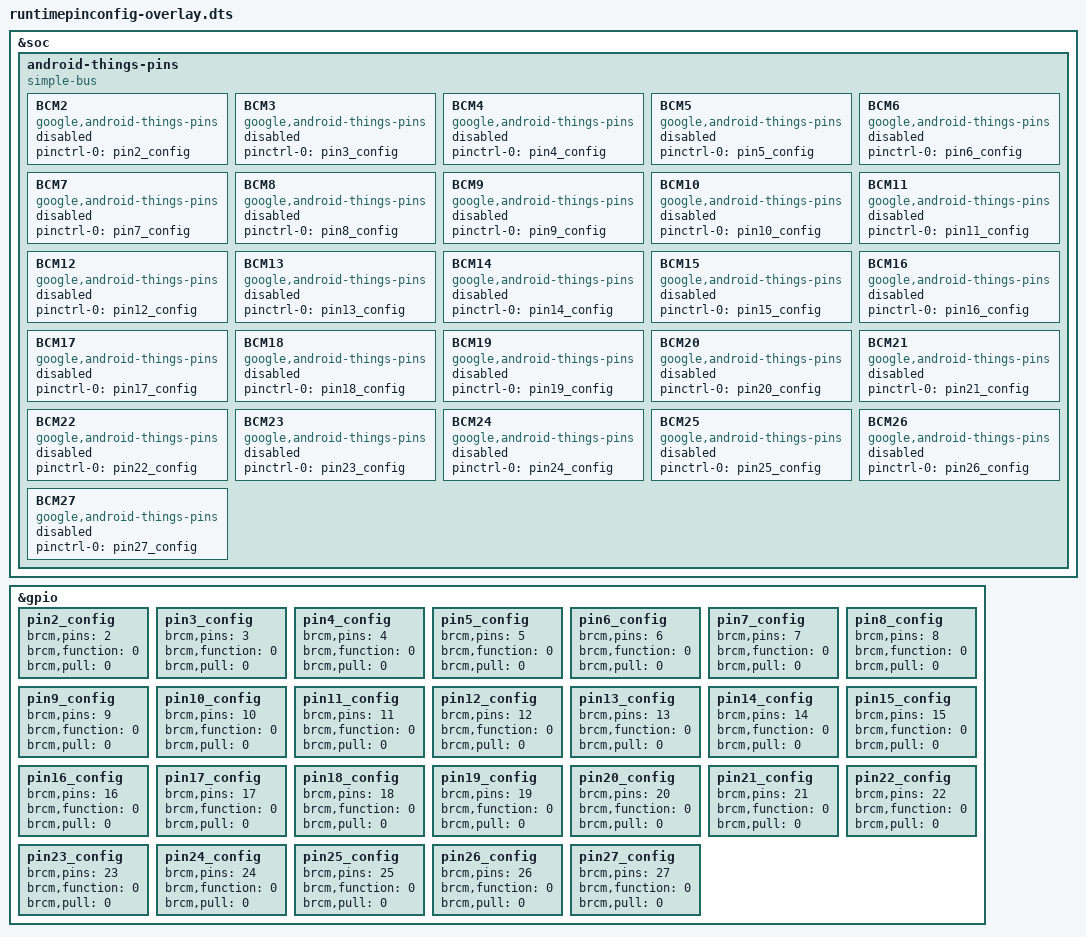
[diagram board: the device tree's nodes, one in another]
/dts-v1/;
/plugin/;

/ {
  fragment@0 {
    target = <&soc>;
    __overlay__ {
      android-things-pins {
        compatible = "simple-bus";

        BCM2 {
          compatible = "google,android-things-pins";
          pinctrl-names = "default";
          pinctrl-0 = <&pin2_config>;
          status = "disabled";
        };

        BCM3 {
          compatible = "google,android-things-pins";
          pinctrl-names = "default";
          pinctrl-0 = <&pin3_config>;
          status = "disabled";
        };

        BCM4 {
          compatible = "google,android-things-pins";
          pinctrl-names = "default";
          pinctrl-0 = <&pin4_config>;
          status = "disabled";
        };

        BCM5 {
          compatible = "google,android-things-pins";
          pinctrl-names = "default";
          pinctrl-0 = <&pin5_config>;
          status = "disabled";
        };

        BCM6 {
          compatible = "google,android-things-pins";
          pinctrl-names = "default";
          pinctrl-0 = <&pin6_config>;
          status = "disabled";
        };

        BCM7 {
          compatible = "google,android-things-pins";
          pinctrl-names = "default";
          pinctrl-0 = <&pin7_config>;
          status = "disabled";
        };

        BCM8 {
          compatible = "google,android-things-pins";
          pinctrl-names = "default";
          pinctrl-0 = <&pin8_config>;
          status = "disabled";
        };

        BCM9 {
          compatible = "google,android-things-pins";
          pinctrl-names = "default";
          pinctrl-0 = <&pin9_config>;
          status = "disabled";
        };

        BCM10 {
          compatible = "google,android-things-pins";
          pinctrl-names = "default";
          pinctrl-0 = <&pin10_config>;
          status = "disabled";
        };

        BCM11 {
          compatible = "google,android-things-pins";
          pinctrl-names = "default";
          pinctrl-0 = <&pin11_config>;
          status = "disabled";
        };

        BCM12 {
          compatible = "google,android-things-pins";
          pinctrl-names = "default";
          pinctrl-0 = <&pin12_config>;
          status = "disabled";
        };

        BCM13 {
          compatible = "google,android-things-pins";
          pinctrl-names = "default";
          pinctrl-0 = <&pin13_config>;
          status = "disabled";
        };

        BCM14 {
          compatible = "google,android-things-pins";
          pinctrl-names = "default";
          pinctrl-0 = <&pin14_config>;
          status = "disabled";
        };

        BCM15 {
          compatible = "google,android-things-pins";
          pinctrl-names = "default";
          pinctrl-0 = <&pin15_config>;
          status = "disabled";
        };

        BCM16 {
          compatible = "google,android-things-pins";
          pinctrl-names = "default";
          pinctrl-0 = <&pin16_config>;
          status = "disabled";
        };

        BCM17 {
          compatible = "google,android-things-pins";
          pinctrl-names = "default";
          pinctrl-0 = <&pin17_config>;
          status = "disabled";
        };

        BCM18 {
          compatible = "google,android-things-pins";
          pinctrl-names = "default";
          pinctrl-0 = <&pin18_config>;
          status = "disabled";
        };

        BCM19 {
          compatible = "google,android-things-pins";
          pinctrl-names = "default";
          pinctrl-0 = <&pin19_config>;
          status = "disabled";
        };

        BCM20 {
          compatible = "google,android-things-pins";
          pinctrl-names = "default";
          pinctrl-0 = <&pin20_config>;
          status = "disabled";
        };

        BCM21 {
          compatible = "google,android-things-pins";
          pinctrl-names = "default";
          pinctrl-0 = <&pin21_config>;
          status = "disabled";
        };

        BCM22 {
          compatible = "google,android-things-pins";
          pinctrl-names = "default";
          pinctrl-0 = <&pin22_config>;
          status = "disabled";
        };

        BCM23 {
          compatible = "google,android-things-pins";
          pinctrl-names = "default";
          pinctrl-0 = <&pin23_config>;
          status = "disabled";
        };

        BCM24 {
          compatible = "google,android-things-pins";
          pinctrl-names = "default";
          pinctrl-0 = <&pin24_config>;
          status = "disabled";
        };

        BCM25 {
          compatible = "google,android-things-pins";
          pinctrl-names = "default";
          pinctrl-0 = <&pin25_config>;
          status = "disabled";
        };

        BCM26 {
          compatible = "google,android-things-pins";
          pinctrl-names = "default";
          pinctrl-0 = <&pin26_config>;
          status = "disabled";
        };

        BCM27 {
          compatible = "google,android-things-pins";
          pinctrl-names = "default";
          pinctrl-0 = <&pin27_config>;
          status = "disabled";
        };
      };
    };
  };

  fragment@1 {
    target = <&gpio>;
    __overlay__ {
      pin2_config: pin2_config {
        brcm,pins = <2>;
        brcm,function = <0>;
        brcm,pull = <0>;
      };

      pin3_config: pin3_config {
        brcm,pins = <3>;
        brcm,function = <0>;
        brcm,pull = <0>;
      };

      pin4_config: pin4_config {
        brcm,pins = <4>;
        brcm,function = <0>;
        brcm,pull = <0>;
      };

      pin5_config: pin5_config {
        brcm,pins = <5>;
        brcm,function = <0>;
        brcm,pull = <0>;
      };

      pin6_config: pin6_config {
        brcm,pins = <6>;
        brcm,function = <0>;
        brcm,pull = <0>;
      };

      pin7_config: pin7_config {
        brcm,pins = <7>;
        brcm,function = <0>;
        brcm,pull = <0>;
      };

      pin8_config: pin8_config {
        brcm,pins = <8>;
        brcm,function = <0>;
        brcm,pull = <0>;
      };

      pin9_config: pin9_config {
        brcm,pins = <9>;
        brcm,function = <0>;
        brcm,pull = <0>;
      };

      pin10_config: pin10_config {
        brcm,pins = <10>;
        brcm,function = <0>;
        brcm,pull = <0>;
      };

      pin11_config: pin11_config {
        brcm,pins = <11>;
        brcm,function = <0>;
        brcm,pull = <0>;
      };

      pin12_config: pin12_config {
        brcm,pins = <12>;
        brcm,function = <0>;
        brcm,pull = <0>;
      };

      pin13_config: pin13_config {
        brcm,pins = <13>;
        brcm,function = <0>;
        brcm,pull = <0>;
      };

      pin14_config: pin14_config {
        brcm,pins = <14>;
        brcm,function = <0>;
        brcm,pull = <0>;
      };

      pin15_config: pin15_config {
        brcm,pins = <15>;
        brcm,function = <0>;
        brcm,pull = <0>;
      };

      pin16_config: pin16_config {
        brcm,pins = <16>;
        brcm,function = <0>;
        brcm,pull = <0>;
      };

      pin17_config: pin17_config {
        brcm,pins = <17>;
        brcm,function = <0>;
        brcm,pull = <0>;
      };

      pin18_config: pin18_config {
        brcm,pins = <18>;
        brcm,function = <0>;
        brcm,pull = <0>;
      };

      pin19_config: pin19_config {
        brcm,pins = <19>;
        brcm,function = <0>;
        brcm,pull = <0>;
      };

      pin20_config: pin20_config {
        brcm,pins = <20>;
        brcm,function = <0>;
        brcm,pull = <0>;
      };

      pin21_config: pin21_config {
        brcm,pins = <21>;
        brcm,function = <0>;
        brcm,pull = <0>;
      };

      pin22_config: pin22_config {
        brcm,pins = <22>;
        brcm,function = <0>;
        brcm,pull = <0>;
      };

      pin23_config: pin23_config {
        brcm,pins = <23>;
        brcm,function = <0>;
        brcm,pull = <0>;
      };

      pin24_config: pin24_config {
        brcm,pins = <24>;
        brcm,function = <0>;
        brcm,pull = <0>;
      };

      pin25_config: pin25_config {
        brcm,pins = <25>;
        brcm,function = <0>;
        brcm,pull = <0>;
      };

      pin26_config: pin26_config {
        brcm,pins = <26>;
        brcm,function = <0>;
        brcm,pull = <0>;
      };

      pin27_config: pin27_config {
        brcm,pins = <27>;
        brcm,function = <0>;
        brcm,pull = <0>;
      };
    };
  };
};
